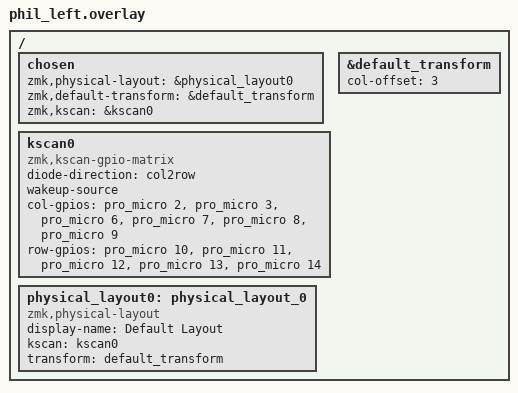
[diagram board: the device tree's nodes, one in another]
#include <dt-bindings/zmk/matrix_transform.h>
#include "phil.dtsi"

/ {
    chosen {
        zmk,physical-layout = &physical_layout0;
        zmk,default-transform = &default_transform;
        zmk,kscan = &kscan0;
    };

    kscan0: kscan0 {
        compatible = "zmk,kscan-gpio-matrix";
        diode-direction = "col2row";
        wakeup-source;

        col-gpios = <&pro_micro 2 GPIO_ACTIVE_HIGH>,
                    <&pro_micro 3 GPIO_ACTIVE_HIGH>,
                    <&pro_micro 6 GPIO_ACTIVE_HIGH>,
                    <&pro_micro 7 GPIO_ACTIVE_HIGH>,
                    <&pro_micro 8 GPIO_ACTIVE_HIGH>,
                    <&pro_micro 9 GPIO_ACTIVE_HIGH>;

        row-gpios = <&pro_micro 10 (GPIO_ACTIVE_HIGH | GPIO_PULL_DOWN)>,
                    <&pro_micro 11 (GPIO_ACTIVE_HIGH | GPIO_PULL_DOWN)>,
                    <&pro_micro 12 (GPIO_ACTIVE_HIGH | GPIO_PULL_DOWN)>,
                    <&pro_micro 13 (GPIO_ACTIVE_HIGH | GPIO_PULL_DOWN)>,
                    <&pro_micro 14 (GPIO_ACTIVE_HIGH | GPIO_PULL_DOWN)>;
    };

    &default_transform {
        col-offset = <3>;
    };

    physical_layout0: physical_layout_0 { 
        compatible = "zmk,physical-layout";
        display-name = "Default Layout";
        kscan = <&kscan0>; 
        transform = <&default_transform>;
    };
};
